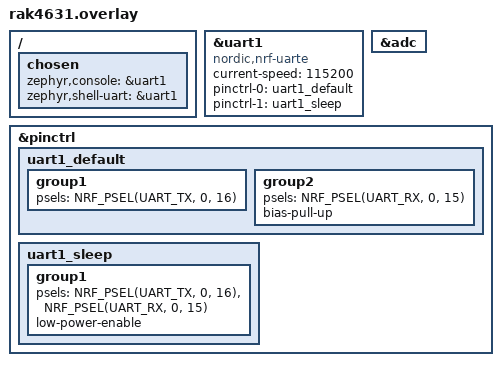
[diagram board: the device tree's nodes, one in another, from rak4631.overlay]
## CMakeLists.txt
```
cmake_minimum_required(VERSION 3.20.0)
find_package(Zephyr REQUIRED HINTS $ENV{ZEPHYR_BASE})
project(adc_test_node)

target_sources(app PRIVATE src/main.c)
```

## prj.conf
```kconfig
CONFIG_SERIAL=y
CONFIG_CONSOLE=y
CONFIG_UART_CONSOLE=y
CONFIG_PRINTK=y
CONFIG_GPIO=y

CONFIG_ADC=y
CONFIG_ADC_NRFX_SAADC=y

CONFIG_MAIN_STACK_SIZE=4096
```

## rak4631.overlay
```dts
/*
 * ADC battery test - Node (Link)
 * Console: uart1 (P0.16 TX / P0.15 RX) @ 115200 → ttyUSB0
 * BAT_AIN: P0.31 / AIN7
 * 분압: 1M / 1M → V_pin × 2 = VBAT
 */

/ {
	chosen {
		zephyr,console = &uart1;
		zephyr,shell-uart = &uart1;
	};
};

&uart1 {
	compatible = "nordic,nrf-uarte";
	status = "okay";
	current-speed = <115200>;
	pinctrl-0 = <&uart1_default>;
	pinctrl-1 = <&uart1_sleep>;
	pinctrl-names = "default", "sleep";
};

&adc {
	status = "okay";
};

&pinctrl {
	uart1_default: uart1_default {
		group1 {
			psels = <NRF_PSEL(UART_TX, 0, 16)>;
		};
		group2 {
			psels = <NRF_PSEL(UART_RX, 0, 15)>;
			bias-pull-up;
		};
	};

	uart1_sleep: uart1_sleep {
		group1 {
			psels = <NRF_PSEL(UART_TX, 0, 16)>,
				<NRF_PSEL(UART_RX, 0, 15)>;
			low-power-enable;
		};
	};
};
```

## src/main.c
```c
/*
 * ADC battery voltage test - Node (Link)
 *
 * Link BAT_AIN: P0.31 = AIN7
 * 분압: 1M / 1M → 보정 배수 = 2
 *
 * SAADC: 12-bit, Gain 1/6, Internal 0.6V ref
 *   ADC 풀스케일 = 0.6V × 6 = 3.6V
 *   ADC mV = (raw / 4096) × 3600
 *   VBAT mV = ADC mV × 2
 *
 * 출처: kc_cert/hwTest_adc 패턴
 */

#include <zephyr/kernel.h>
#include <zephyr/device.h>
#include <zephyr/drivers/adc.h>

#define ADC_CHANNEL     7        /* AIN7 */
#define ADC_RESOLUTION  12

#define DIVIDER_NUM     2
#define DIVIDER_DEN     1

static const struct device *adc_dev;
static int16_t adc_buffer;

static struct adc_channel_cfg channel_cfg = {
	.gain             = ADC_GAIN_1_6,
	.reference        = ADC_REF_INTERNAL,
	.acquisition_time = ADC_ACQ_TIME(ADC_ACQ_TIME_MICROSECONDS, 40),
	.channel_id       = ADC_CHANNEL,
	.input_positive   = SAADC_CH_PSELP_PSELP_AnalogInput7,
};

static struct adc_sequence sequence = {
	.channels    = BIT(ADC_CHANNEL),
	.buffer      = &adc_buffer,
	.buffer_size = sizeof(adc_buffer),
	.resolution  = ADC_RESOLUTION,
};

int main(void)
{
	int ret;

	printk("\n========================================\n");
	printk("  ADC Battery test - Node (Link)\n");
	printk("  BAT_AIN: P0.31 (AIN7)\n");
	printk("  Divider: 1M / 1M  → x%d\n", DIVIDER_NUM / DIVIDER_DEN);
	printk("  ADC: 12bit, Gain 1/6, Ref 0.6V (full=3.6V)\n");
	printk("========================================\n\n");

	adc_dev = DEVICE_DT_GET(DT_NODELABEL(adc));
	if (!device_is_ready(adc_dev)) {
		printk("[ADC] device NOT ready\n");
		return -1;
	}

	ret = adc_channel_setup(adc_dev, &channel_cfg);
	if (ret < 0) {
		printk("[ADC] channel setup failed: %d\n", ret);
		return -1;
	}
	printk("[ADC] AIN7 ready\n\n");

	while (1) {
		ret = adc_read(adc_dev, &sequence);
		if (ret < 0) {
			printk("[ADC] read error: %d\n", ret);
		} else {
			int32_t raw = adc_buffer;
			if (raw < 0) raw = 0;

			int32_t adc_mv = (raw * 3600) / 4096;
			int32_t bat_mv = (adc_mv * DIVIDER_NUM) / DIVIDER_DEN;

			printk("[ADC] raw=%4d  pin=%4d mV  VBAT=%5d mV (%d.%03d V)\n",
			       (int)raw, (int)adc_mv, (int)bat_mv,
			       (int)(bat_mv / 1000), (int)(bat_mv % 1000));
		}
		k_sleep(K_MSEC(1000));
	}

	return 0;
}
```
